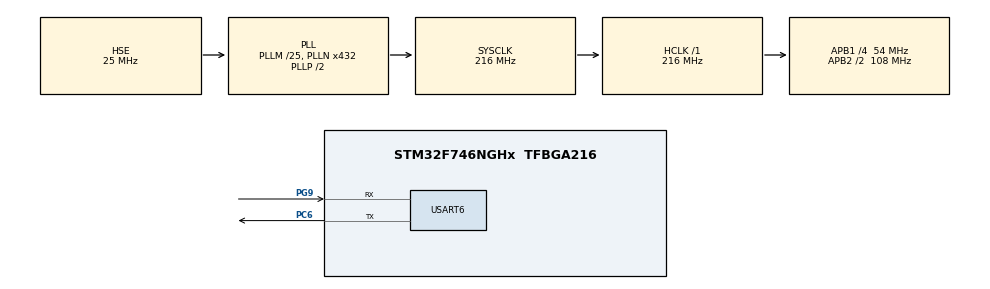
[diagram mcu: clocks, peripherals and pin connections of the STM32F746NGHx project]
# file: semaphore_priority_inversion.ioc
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FREERTOS.BinarySemaphores01=BinSem,Dynamic,NULL,Available
FREERTOS.Tasks01=NormalTask,0,128,StartNormalTask,Default,NULL,Dynamic,NULL,NULL;HighTask,1,128,StartHighTask,Default,NULL,Dynamic,NULL,NULL;LowTask,-1,128,StartLowTask,Default,NULL,Dynamic,NULL,NULL
Mcu.Family=STM32F7
Mcu.Name=STM32F746NGHx
Mcu.Package=TFBGA216
NVIC.PriorityGroup=NVIC_PRIORITYGROUP_4
NVIC.TIM1_UP_TIM10_IRQn=true\:15\:0\:false\:false\:true\:false\:false\:true\:true
NVIC.TimeBase=TIM1_UP_TIM10_IRQn
NVIC.TimeBaseIP=TIM1
PC6.Mode=Asynchronous
PC6.Signal=USART6_TX
PG9.Mode=Asynchronous
PG9.Signal=USART6_RX
PH0/OSC_IN.Mode=HSE-External-Oscillator
PH0/OSC_IN.Signal=RCC_OSC_IN
PH1/OSC_OUT.Mode=HSE-External-Oscillator
PH1/OSC_OUT.Signal=RCC_OSC_OUT
ProjectManager.HeapSize=0x200
ProjectManager.StackSize=0x400
ProjectManager.TargetToolchain=STM32CubeIDE
RCC.AHBFreq_Value=216000000
RCC.APB1CLKDivider=RCC_HCLK_DIV4
RCC.APB1Freq_Value=54000000
RCC.APB1TimFreq_Value=108000000
RCC.APB2CLKDivider=RCC_HCLK_DIV2
RCC.APB2Freq_Value=108000000
RCC.APB2TimFreq_Value=216000000
RCC.CortexFreq_Value=216000000
RCC.HCLKFreq_Value=216000000
RCC.HSE_VALUE=25000000
RCC.HSI_VALUE=16000000
RCC.PLL48CLockSelection=RCC_CLK48SOURCE_PLLSAIP
RCC.PLLI2SN=100
RCC.PLLM=25
RCC.PLLN=432
RCC.PLLQ=9
RCC.PLLSAIN=384
RCC.PLLSAIP=RCC_PLLSAIP_DIV8
RCC.PLLSAIR=5
RCC.PLLSAIRDiv=RCC_PLLSAIDIVR_8
RCC.PLLSourceVirtual=RCC_PLLSOURCE_HSE
RCC.SDMMCClockSelection=RCC_SDMMC1CLKSOURCE_CLK48
RCC.SYSCLKFreq_VALUE=216000000
RCC.SYSCLKSource=RCC_SYSCLKSOURCE_PLLCLK
RCC.USBFreq_Value=48000000
RCC.VCOOutputFreq_Value=432000000
USART6.VirtualMode-Asynchronous=VM_ASYNC
VP_FREERTOS_VS_CMSIS_V1.Mode=CMSIS_V1
VP_SYS_VS_tim1.Mode=TIM1
board=STM32F746G-DISCO

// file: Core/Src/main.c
/* USER CODE BEGIN Header */
/**
  ******************************************************************************
  * @file           : main.c
  * @brief          : Main program body
  ******************************************************************************
  * @attention
  *
  * Copyright (c) 2025 STMicroelectronics.
  * All rights reserved.
  *
  * This software is licensed under terms that can be found in the LICENSE file
  * in the root directory of this software component.
  * If no LICENSE file comes with this software, it is provided AS-IS.
  *
  ******************************************************************************
  */
/* USER CODE END Header */
#include "main.h"
#include "cmsis_os.h"
#include "string.h"

UART_HandleTypeDef huart6;

osThreadId NormalTaskHandle;
osThreadId HighTaskHandle;
osThreadId LowTaskHandle;
osSemaphoreId BinSemHandle;

void SystemClock_Config(void);
static void MX_GPIO_Init(void);
static void MX_USART6_UART_Init(void);
void StartNormalTask(void const * argument);
void StartHighTask(void const * argument);
void StartLowTask(void const * argument);

int main(void)
{

  /* MCU Configuration--------------------------------------------------------*/

  /* Reset of all peripherals, Initializes the Flash interface and the Systick. */
  HAL_Init();

  /* Configure the system clock */
  SystemClock_Config();

  /* Initialize all configured peripherals */
  MX_GPIO_Init();
  MX_USART6_UART_Init();

  /* Create the semaphores(s) */
  /* definition and creation of BinSem */
  osSemaphoreDef(BinSem);
  BinSemHandle = osSemaphoreCreate(osSemaphore(BinSem), 1);

  /* Create the thread(s) */
  /* definition and creation of NormalTask */
  osThreadDef(NormalTask, StartNormalTask, osPriorityNormal, 0, 128);
  NormalTaskHandle = osThreadCreate(osThread(NormalTask), NULL);

  /* definition and creation of HighTask */
  osThreadDef(HighTask, StartHighTask, osPriorityAboveNormal, 0, 128);
  HighTaskHandle = osThreadCreate(osThread(HighTask), NULL);

  /* definition and creation of LowTask */
  osThreadDef(LowTask, StartLowTask, osPriorityBelowNormal, 0, 128);
  LowTaskHandle = osThreadCreate(osThread(LowTask), NULL);

  /* Start scheduler */
  osKernelStart();

  /* We should never get here as control is now taken by the scheduler */

  /* Infinite loop */
  while (1)
  {

  }
}

void SystemClock_Config(void)
{
  RCC_OscInitTypeDef RCC_OscInitStruct = {0};
  RCC_ClkInitTypeDef RCC_ClkInitStruct = {0};

  /** Configure the main internal regulator output voltage
  */
  __HAL_RCC_PWR_CLK_ENABLE();
  __HAL_PWR_VOLTAGESCALING_CONFIG(PWR_REGULATOR_VOLTAGE_SCALE1);

  /** Initializes the RCC Oscillators according to the specified parameters
  * in the RCC_OscInitTypeDef structure.
  */
  RCC_OscInitStruct.OscillatorType = RCC_OSCILLATORTYPE_HSE;
  RCC_OscInitStruct.HSEState = RCC_HSE_ON;
  RCC_OscInitStruct.PLL.PLLState = RCC_PLL_ON;
  RCC_OscInitStruct.PLL.PLLSource = RCC_PLLSOURCE_HSE;
  RCC_OscInitStruct.PLL.PLLM = 25;
  RCC_OscInitStruct.PLL.PLLN = 432;
  RCC_OscInitStruct.PLL.PLLP = RCC_PLLP_DIV2;
  RCC_OscInitStruct.PLL.PLLQ = 9;
  if (HAL_RCC_OscConfig(&RCC_OscInitStruct) != HAL_OK)
  {
    Error_Handler();
  }

  /** Activate the Over-Drive mode
  */
  if (HAL_PWREx_EnableOverDrive() != HAL_OK)
  {
    Error_Handler();
  }

  /** Initializes the CPU, AHB and APB buses clocks
  */
  RCC_ClkInitStruct.ClockType = RCC_CLOCKTYPE_HCLK|RCC_CLOCKTYPE_SYSCLK
                              |RCC_CLOCKTYPE_PCLK1|RCC_CLOCKTYPE_PCLK2;
  RCC_ClkInitStruct.SYSCLKSource = RCC_SYSCLKSOURCE_PLLCLK;
  RCC_ClkInitStruct.AHBCLKDivider = RCC_SYSCLK_DIV1;
  RCC_ClkInitStruct.APB1CLKDivider = RCC_HCLK_DIV4;
  RCC_ClkInitStruct.APB2CLKDivider = RCC_HCLK_DIV2;

  if (HAL_RCC_ClockConfig(&RCC_ClkInitStruct, FLASH_LATENCY_7) != HAL_OK)
  {
    Error_Handler();
  }
}

static void MX_USART6_UART_Init(void)
{

  huart6.Instance = USART6;
  huart6.Init.BaudRate = 115200;
  huart6.Init.WordLength = UART_WORDLENGTH_8B;
  huart6.Init.StopBits = UART_STOPBITS_1;
  huart6.Init.Parity = UART_PARITY_NONE;
  huart6.Init.Mode = UART_MODE_TX_RX;
  huart6.Init.HwFlowCtl = UART_HWCONTROL_NONE;
  huart6.Init.OverSampling = UART_OVERSAMPLING_16;
  huart6.Init.OneBitSampling = UART_ONE_BIT_SAMPLE_DISABLE;
  huart6.AdvancedInit.AdvFeatureInit = UART_ADVFEATURE_NO_INIT;
  if (HAL_UART_Init(&huart6) != HAL_OK)
  {
    Error_Handler();
  }

}

static void MX_GPIO_Init(void)
{

  /* GPIO Ports Clock Enable */
  __HAL_RCC_GPIOG_CLK_ENABLE();
  __HAL_RCC_GPIOH_CLK_ENABLE();
  __HAL_RCC_GPIOC_CLK_ENABLE();

}

void StartNormalTask(void const * argument)
{
  /* USER CODE BEGIN 5 */
  /* Infinite loop */
  for(;;)
  {
	char *str1 = "Entered MediumTask, running without semaphore\r\n";
	HAL_UART_Transmit(&huart6, (uint8_t *) str1, strlen(str1), 100);

	//osSemaphoreWait(BimSemHandle, osWaitForever);

	//char *str3= "Semaphore acquired by MediumTask\r\n";
	//HAL_UART_Transmit(&huart6, (uint8_t *) str3, strlen(str3), 100);

	char *str2= "Leaving MediumTask \r\n\n";
	HAL_UART_Transmit(&huart6, (uint8_t *) str2, strlen(str2), 100);

	//osSemaphoreRelease(BimSemHandle);
  	osDelay(500);
	}
	    /* USER CODE END 5 */
}
void StartHighTask(void const * argument)
{
	    /* USER CODE BEGIN StartHighTask */
	    /* Infinite loop */
  for(;;)
    {
	  	char *str1 = "Entered HighTask and waiting for semaphore\r\n";
	  	HAL_UART_Transmit(&huart6, (uint8_t *) str1, strlen(str1), 100);

	  	osSemaphoreWait(BinSemHandle, osWaitForever);

	  	char *str3= "Semaphore acquired by MediumTask\r\n";
	  	HAL_UART_Transmit(&huart6, (uint8_t *) str3, strlen(str3), 100);

	  	char *str2= "Leaving HighTask and releasing Semaphore\r\n\n";
	  	HAL_UART_Transmit(&huart6, (uint8_t *) str2, strlen(str2), 100);

	  	osSemaphoreRelease(BinSemHandle);

	      osDelay(500);
    }
   /* USER CODE END StartHighTask */
}

void StartLowTask(void const * argument)
{
	    /* USER CODE BEGIN StartLowTask */
	    /* Infinite loop */
  for(;;)
   {

	  	char *str1 = "Entered LowTask and waiting for semaphore\r\n"; //<-----------------------\r\n used for
	  	/*
	  	 * \r(carriage return) : returning cursor to the beginning of current line
	  	 * \n(new line)		   : returning cursor to new line in linux terminal
	  	 * */
	  	HAL_UART_Transmit(&huart6, (uint8_t *) str1, strlen(str1), 100);

	  	osSemaphoreWait(BinSemHandle, osWaitForever);

	  	char *str3= "Semaphore acquired by LowTask\r\n";
	  	HAL_UART_Transmit(&huart6, (uint8_t *) str3, strlen(str3), 100);

	  	HAL_Delay(50000);
	  	//push button to observe preemption
	  	//to avoid preemption and to safeguard the resources we use semaphores
	  	char *str2= "Leaving LowTask and releasing semaphore\r\n\n";
	  	HAL_UART_Transmit(&huart6, (uint8_t *) str2, strlen(str2), 100);

	  	osSemaphoreRelease(BinSemHandle);

	  	osDelay(500);
   }
   /* USER CODE END StartLowTask */
}

void HAL_TIM_PeriodElapsedCallback(TIM_HandleTypeDef *htim)
{
  if (htim->Instance == TIM1)
  {
    HAL_IncTick();
  }
}

void Error_Handler(void)
{
  __disable_irq();
  while (1)
  {
  }
}
